# MSP430G2X52 register map
Vendor: msp430gen; File version: v0.4.0-16-g4f822b9
Registers are 8-bit, read-write, reset 0x0 unless marked. A register's access mark holds for its fields unless they carry their own. Offsets are from the block's base; [hi:lo] are bit positions.

## SYSTEM_CLOCK
Base 0x00000052
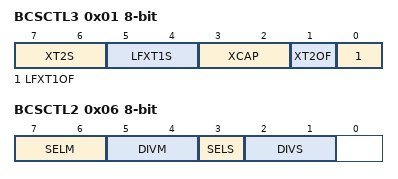
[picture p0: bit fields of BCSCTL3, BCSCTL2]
0x01 BCSCTL3 — Basic Clock System Control 3
  [7:6] XT2S — Mode 0 for XT2
    0=Mode 0 for XT2 : 0.4 - 1 MHz; 1=Mode 1 for XT2 : 1 - 4 MHz; 2=Mode 2 for XT2 : 2 - 16 MHz; 3=Mode 3 for XT2 : Digital input signal
  [5:4] LFXT1S — Mode 0 for LFXT1 (XTS = 0)
    0=Mode 0 for LFXT1 : Normal operation; 1=Mode 1 for LFXT1 : Reserved; 2=Mode 2 for LFXT1 : VLO; 3=Mode 3 for LFXT1 : Digital input signal
  [3:2] XCAP — XIN/XOUT Cap 0
    0=XIN/XOUT Cap : 0 pF; 1=XIN/XOUT Cap : 6 pF; 2=XIN/XOUT Cap : 10 pF; 3=XIN/XOUT Cap : 12.5 pF
  [1] XT2OF — High frequency oscillator 2 fault flag
  [0] LFXT1OF — Low/high Frequency Oscillator Fault Flag
0x04 DCOCTL — DCO Clock Frequency Control
  [7:5] DCO — DCO Select Bit 0
  [7:0] DCOCTL — DCO Clock Frequency Control register
  [4:0] MOD — Modulation Bit 0
0x05 BCSCTL1 — Basic Clock System Control 1
  [7] XT2OFF — Enable XT2CLK
  [6] XTS — LFXTCLK 0:Low Freq. / 1: High Freq.
  [5:4] DIVA — ACLK Divider 0
    0=ACLK Divider 0: /1; 1=ACLK Divider 1: /2; 2=ACLK Divider 2: /4; 3=ACLK Divider 3: /8
  [7:0] BCSCTL1 — Basic Clock System Control 1 register
  [3:0] RSEL — Range Select Bit 0
0x06 BCSCTL2 — Basic Clock System Control 2
  [7:6] SELM — MCLK Source Select 0
    0=MCLK Source Select 0: DCOCLK; 1=MCLK Source Select 1: DCOCLK; 2=MCLK Source Select 2: XT2CLK/LFXTCLK; 3=MCLK Source Select 3: LFXTCLK
  [5:4] DIVM — MCLK Divider 0
    0=MCLK Divider 0: /1; 1=MCLK Divider 1: /2; 2=MCLK Divider 2: /4; 3=MCLK Divider 3: /8
  [3] SELS — SMCLK Source Select 0:DCOCLK / 1:XT2CLK/LFXTCLK
  [2:1] DIVS — SMCLK Divider 0
    0=SMCLK Divider 0: /1; 1=SMCLK Divider 1: /2; 2=SMCLK Divider 2: /4; 3=SMCLK Divider 3: /8

## COMPARATOR_A
Base 0x00000058
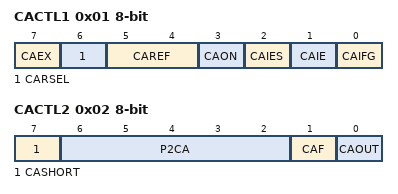
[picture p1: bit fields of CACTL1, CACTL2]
0x01 CACTL1 — Comparator A Control 1
  [7] CAEX — Comp. A Exchange Inputs
  [6] CARSEL — Comp. A Internal Reference Enable
  [5:4] CAREF — Comp. A Internal Reference Select 0
    0=Comp. A Int. Ref. Select 0 : Off; 1=Comp. A Int. Ref. Select 1 : 0.25*Vcc; 2=Comp. A Int. Ref. Select 2 : 0.5*Vcc; 3=Comp. A Int. Ref. Select 3 : Vt
  [3] CAON — Comp. A enable
  [2] CAIES — Comp. A Int. Edge Select: 0:rising / 1:falling
  [1] CAIE — Comp. A Interrupt Enable
  [0] CAIFG — Comp. A Interrupt Flag
0x02 CACTL2 — Comparator A Control 2
  [7] CASHORT — Comp. A Short + and - Terminals
  [6:2] P2CA — Comp. A +Terminal Multiplexer
    0=NONE_NONE (No + or - connection); 1=CA0_NONE (Connect + to CA0, no connection to -); 2=NONE_CA1 (No connection to +, connect - to CA1); 3=CA0_CA1 (Connect + to CA0, connect - to CA1); 4=NONE_CA2 (No connection to +, connect - to CA2); 5=CA0_CA2 (Connect + to CA0, connect - to CA2); 6=NONE_CA3 (No connection to +, connect - to CA3); 7=CA0_CA3 (Connect + to CA0, connect - to CA3); 8=NONE_CA4 (No connection to +, connect - to CA4); 9=CA0_CA4 (Connect + to CA0, connect - to CA4); 10=NONE_CA5 (No connection to +, connect - to CA5); 11=CA0_CA5 (Connect + to CA0, connect - to CA5); 12=NONE_CA6 (No connection to +, connect - to CA6); 13=CA0_CA6 (Connect + to CA0, connect - to CA6); 14=NONE_CA7 (No connection to +, connect - to CA7); 15=CA0_CA7 (Connect + to CA0, connect - to CA7); 16=CA1_NONE (Connect + to CA1, no connection to -); 17=CA2_NONE (Connect + to CA2, no connection to -); 18=CA1_CA1 (Connect + to CA1, connect - to CA1); 19=CA2_CA1 (Connect + to CA2, connect - to CA1); 20=CA1_CA2 (Connect + to CA1, connect - to CA2); 21=CA2_CA2 (Connect + to CA2, connect - to CA2); 22=CA1_CA3 (Connect + to CA1, connect - to CA3); 23=CA2_CA3 (Connect + to CA2, connect - to CA3); 24=CA1_CA4 (Connect + to CA1, connect - to CA4); 25=CA2_CA4 (Connect + to CA2, connect - to CA4); 26=CA1_CA5 (Connect + to CA1, connect - to CA5); 27=CA2_CA5 (Connect + to CA2, connect - to CA5); 28=CA1_CA6 (Connect + to CA1, connect - to CA6); 29=CA2_CA6 (Connect + to CA2, connect - to CA6); 30=CA1_CA7 (Connect + to CA1, connect - to CA7); 31=CA2_CA7 (Connect + to CA2, connect - to CA7)
  [1] CAF — Comp. A Enable Output Filter
  [0] CAOUT — Comp. A Output
0x03 CAPD — Comparator A Port Disable
  [7] CAPD7 — Comp. A Disable Input Buffer of Port Register .7
  [6] CAPD6 — Comp. A Disable Input Buffer of Port Register .6
  [5] CAPD5 — Comp. A Disable Input Buffer of Port Register .5
  [4] CAPD4 — Comp. A Disable Input Buffer of Port Register .4
  [3] CAPD3 — Comp. A Disable Input Buffer of Port Register .3
  [2] CAPD2 — Comp. A Disable Input Buffer of Port Register .2
  [1] CAPD1 — Comp. A Disable Input Buffer of Port Register .1
  [0] CAPD0 — Comp. A Disable Input Buffer of Port Register .0
  [7:0] CAPD — Comparator A Port Disable register
